# CH32V307xx register map
Vendor: WCH Ltd.; File version: 1.0
Registers are 32-bit, read-write, reset 0x0 unless marked. A register's access mark holds for its fields unless they carry their own. Offsets are from the block's base; [hi:lo] are bit positions; lines under a group give offsets from that group; {n}, {i} and the like mark numbered series.

## ADC2 — Analog to digital converter
Base 0x40012800
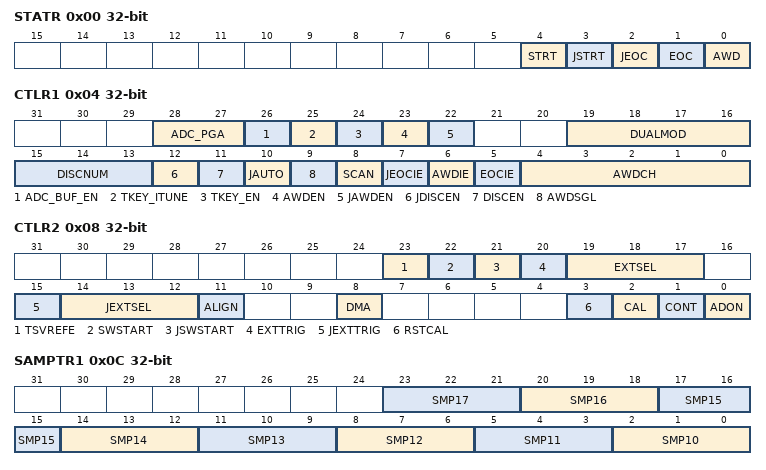
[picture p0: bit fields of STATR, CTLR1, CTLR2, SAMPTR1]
0x00 STATR — status register
  [4] STRT — Regular channel start flag
  [3] JSTRT — Injected channel start flag
  [2] JEOC — Injected channel end of conversion
  [1] EOC — Regular channel end of conversion
  [0] AWD — Analog watchdog flag
0x04 CTLR1 — control register 1
  [28:27] ADC_PGA
  [26] ADC_BUF_EN — TKEY_BUF_Enable
  [25] TKEY_ITUNE — TKEY_I enable
  [24] TKEY_EN — TKEY enable, including TKEY_F and TKEY_V
  [23] AWDEN — Analog watchdog enable on regular channels
  [22] JAWDEN — Analog watchdog enable on injected channels
  [19:16] DUALMOD — Dual mode selection
  [15:13] DISCNUM — Discontinuous mode channel count
  [12] JDISCEN — Discontinuous mode on injected channels
  [11] DISCEN — Discontinuous mode on regular channels
  [10] JAUTO — Automatic injected group conversion
  [9] AWDSGL — Enable the watchdog on a single channel in scan mode
  [8] SCAN — Scan mode
  [7] JEOCIE — Interrupt enable for injected channels
  [6] AWDIE — Analog watchdog interrupt enable
  [5] EOCIE — Interrupt enable for EOC
  [4:0] AWDCH — Analog watchdog channel select bits
0x08 CTLR2 — control register 2
  [23] TSVREFE — Temperature sensor and VREFINT enable
  [22] SWSTART — Start conversion of regular channels
  [21] JSWSTART — Start conversion of injected channels
  [20] EXTTRIG — External trigger conversion mode for regular channels
  [19:17] EXTSEL — External event select for regular group
  [15] JEXTTRIG — External trigger conversion mode for injected channels
  [14:12] JEXTSEL — External event select for injected group
  [11] ALIGN — Data alignment
  [8] DMA — Direct memory access mode
  [3] RSTCAL — Reset calibration
  [2] CAL — A/D calibration
  [1] CONT — Continuous conversion
  [0] ADON — A/D converter ON / OFF
0x0C SAMPTR1 — sample time register 1
  [3n-28:3n-30] SMP{n} (n=10..17) — Channel {n} sample time selection
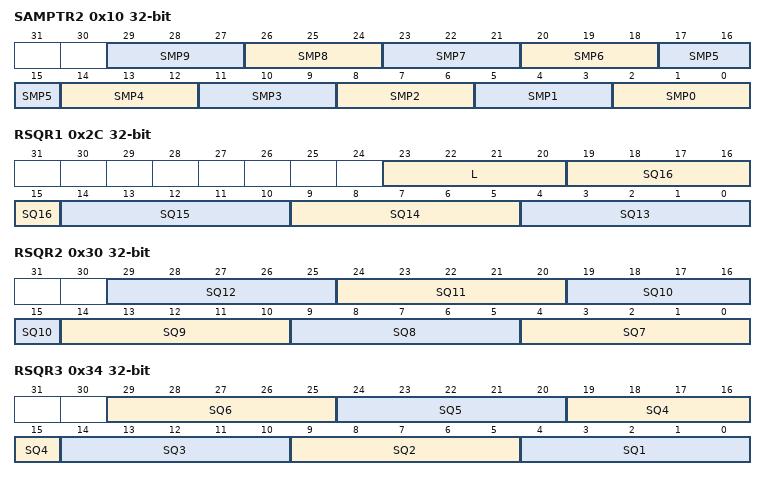
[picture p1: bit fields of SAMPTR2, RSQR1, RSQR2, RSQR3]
0x10 SAMPTR2 — sample time register 2
  [3n+2:3n] SMP{n} (n=0..9) — Channel {n} sample time selection
{0x10+4i} IOFR{i} (i=1..4) — injected channel data offset register x
  [11:0] JOFFSET{i} — Data offset for injected channel x
0x24 WDHTR reset 0xFFF — watchdog higher threshold register
  [11:0] HT — Analog watchdog higher threshold
0x28 WDLTR — watchdog lower threshold register
  [11:0] LT — Analog watchdog lower threshold
0x2C RSQR1 — regular sequence register 1
  [23:20] L — Regular channel sequence length
  [5n-61:5n-65] SQ{n} (n=13..16) — {n}th conversion in regular sequence
0x30 RSQR2 — regular sequence register 2
  [5n-31:5n-35] SQ{n} (n=7..12) — {n}th conversion in regular sequence
0x34 RSQR3 — regular sequence register 3
  [29:25] SQ6 — 6th conversion in regular sequence
  [24:20] SQ5 — 5th conversion in regular sequence
  [19:15] SQ4 — 4th conversion in regular sequence
  [14:10] SQ3 — 3rd conversion in regular sequence
  [9:5] SQ2 — 2nd conversion in regular sequence
  [4:0] SQ1 — 1st conversion in regular sequence
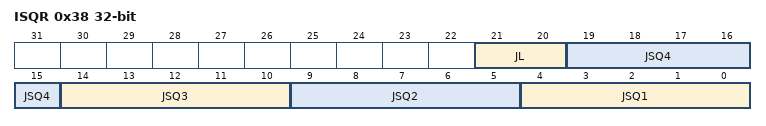
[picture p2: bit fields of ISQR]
0x38 ISQR — injected sequence register
  [21:20] JL — Injected sequence length
  [19:15] JSQ4 — 4th conversion in injected sequence
  [14:10] JSQ3 — 3rd conversion in injected sequence
  [9:5] JSQ2 — 2nd conversion in injected sequence
  [4:0] JSQ1 — 1st conversion in injected sequence
{0x38+4i} IDATAR{i} ro (i=1..4) — injected data register x
  [15:0] JDATA — Injected data
0x4C RDATAR ro — regular data register
  [15:0] DATA — Regular data

## DBG — Debug support
Base 0xE000D000
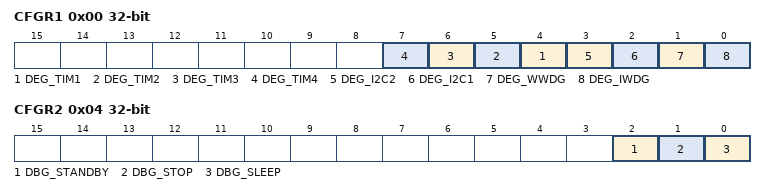
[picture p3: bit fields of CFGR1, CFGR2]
0x00 CFGR1 — DBGMCU_CFGR1
  [n+3] DEG_TIM{n} (n=1..4), [3] DEG_I2C2, [2] DEG_I2C1, [1] DEG_WWDG, [0] DEG_IWDG
0x04 CFGR2 — DBGMCU_CFGR2
  [2] DBG_STANDBY, [1] DBG_STOP, [0] DBG_SLEEP

## CRC — CRC calculation unit
Base 0x40023000
0x00 DATAR reset 0xFFFFFFFF — Data register
  [31:0] DR — Data Register
0x04 IDATAR — Independent Data register
  [7:0] IDR
0x08 CTLR wo — Control register
  [0] RESET — Reset bit

## FLASH
Base 0x40022000
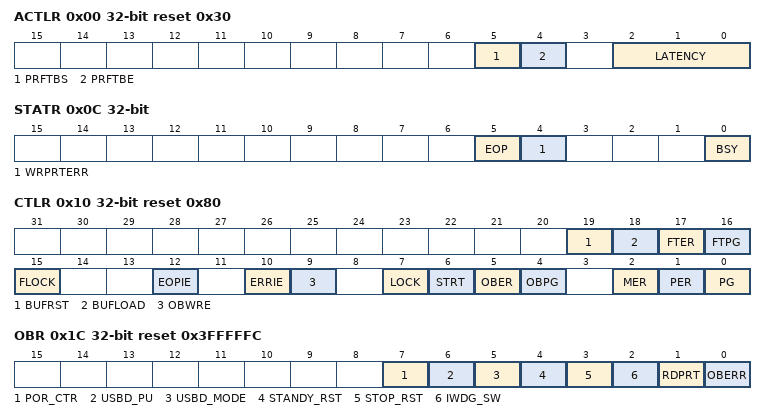
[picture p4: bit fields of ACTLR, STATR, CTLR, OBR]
0x00 ACTLR access per field reset 0x30 — Flash access control register
  [5] PRFTBS ro — Prefetch buffer status
  [4] PRFTBE rw — Prefetch buffer enable
  [2:0] LATENCY rw
0x04 KEYR wo — Flash key register
  [31:0] KEYR — FPEC key
0x08 OBKEYR wo — Flash option key register
  [31:0] OPTKEY — Option byte key
0x0C STATR access per field — Status register
  [5] EOP rw — End of operation
  [4] WRPRTERR rw — Write protection error
  [0] BSY ro — Busy
0x10 CTLR reset 0x80 — Control register
  [19] BUFRST — Buffer reset
  [18] BUFLOAD — Buffer load
  [17] FTER — Fast erase
  [16] FTPG — Fast programming
  [15] FLOCK — Fast programmable lock
  [12] EOPIE — End of operation interrupt enable
  [10] ERRIE — Error interrupt enable
  [9] OBWRE — Option bytes write enable
  [7] LOCK
  [6] STRT — Start
  [5] OBER — Option byte erase
  [4] OBPG — Option byte programming
  [2] MER — Mass Erase
  [1] PER — Page Erase
  [0] PG — Programming
0x14 ADDR wo — Flash address register
  [31:0] FAR — Flash Address
0x1C OBR ro reset 0x3FFFFFC — Option byte register
  [7] POR_CTR
  [6] USBD_PU
  [5] USBD_MODE
  [4] STANDY_RST
  [3] STOP_RST
  [2] IWDG_SW
  [1] RDPRT — Read protection
  [0] OBERR — Option byte error
0x20 WPR ro reset 0xFFFFFFFF — Write protection register
  [31:0] WRP — Write protect
0x24 MODEKEYR wo — Mode select register
  [31:0] MODEKEYR — Mode select

## PFIC — Programmable Fast Interrupt Controller
Base 0xE000E000
0x00 ISR1 ro — Interrupt Status Register
  [31:12] INTENSTA — Interrupt ID Status
0x04 ISR2 ro — Interrupt Status Register
  [3:0] INTENSTA — Interrupt ID Status
0x20 IPR1 ro — Interrupt Pending Register
  [31:12] PENDSTA
0x24 IPR2 ro — Interrupt Pending Register
  [3:0] PENDSTA
0x40 ITHRESDR — Interrupt Priority Register
  [7:0] THRESHOLD
0x44 FIBADDRR — Interrupt Fast Address Register
  [31:28] BASEADDR
0x48 CFGR wo — Interrupt Config Register
  [31:16] KEYCODE
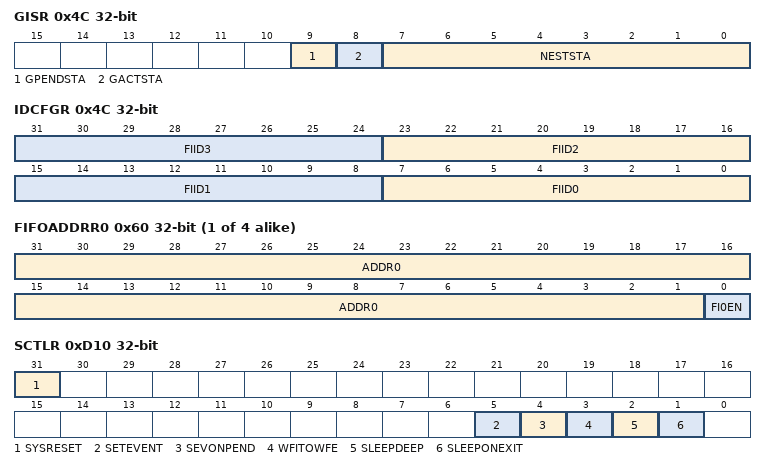
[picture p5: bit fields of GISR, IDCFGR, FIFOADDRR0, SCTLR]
0x4C GISR ro — Interrupt Global Register
  [9] GPENDSTA, [8] GACTSTA, [7:0] NESTSTA
0x4C IDCFGR ro — ID Config Register
  [8n+7:8n] FIID{n} (n=0..3)
0x60 FIFOADDRR{i} (i=0..3) — Interrupt {i} address Register
  [31:1] ADDR{i}, [0] FI{i}EN
0x100 IENR1 — Interrupt Setting Register
  [2:0] INTEN
0x104 IENR2 — Interrupt Setting Register
  [2:0] INTEN
0x180 IRER1 — Interrupt Clear Register
  [32:12] INTRSET
0x184 IRER2 — Interrupt Clear Register
  [2:0] INTRSET
0x200 IPSR1 — Interrupt Pending Register
  [32:12] PENDSET
0x204 IPSR2 — Interrupt Pending Register
  [2:0] PENDSET
0x280 IPRR1 — Interrupt Pending Clear Register
  [32:12] PENDRESET
0x284 IPRR2 — Interrupt Pending Clear Register
  [2:0] PENDRESET
0x300 IACTR1 — Interrupt ACTIVE Register
  [32:12] IACTS
0x304 IACTR2 — Interrupt ACTIVE Register
  [2:0] IACTS
{0x400+i} IPRIOR{i} 8-bit (i=0..247) — Interrupt Priority Register
{0x400+i} IPRIOR{i} 8-bit (i=249..255) — Interrupt Priority Register
0xD10 SCTLR — System Control Register
  [31] SYSRESET, [5] SETEVENT, [4] SEVONPEND, [3] WFITOWFE, [2] SLEEPDEEP, [1] SLEEPONEXIT
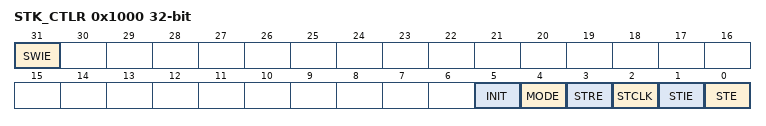
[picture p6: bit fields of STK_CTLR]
0x1000 STK_CTLR — System counter control register
  [31] SWIE — System software triggered interrupts enable
  [5] INIT — System Initialization update
  [4] MODE — System Mode
  [3] STRE — System reload register
  [2] STCLK — System selects the clock source
  [1] STIE — System counter interrupt enable
  [0] STE — System counter enable
0x1004 STK_SR — System START
  [0] CNTIF
0x1004 STK_CNTL — System counter low register
0x1008 STK_CNTH — System counter high register
0x100C STK_CMPLR — System compare low register
  [31:0] CMPL
0x1010 STK_CMPHR — System compare high register
  [31:0] CMPH
0x4F08 IPRIOR248 8-bit — Interrupt Priority Register
